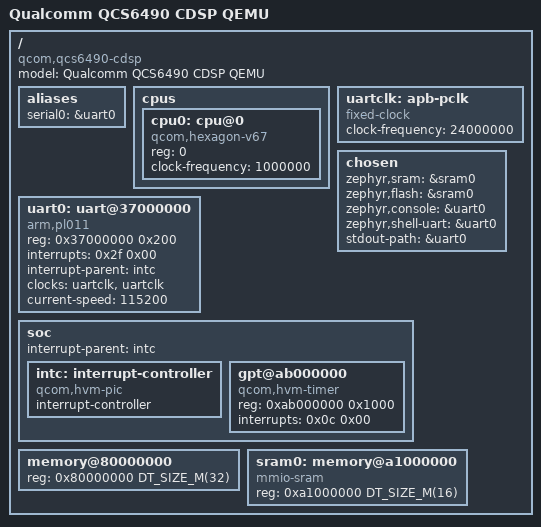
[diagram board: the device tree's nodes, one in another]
/*
 * Copyright (c) Qualcomm Technologies, Inc. and/or its subsidiaries.
 *
 * SPDX-License-Identifier: Apache-2.0
 */

/dts-v1/;

#include <mem.h>

/ {
	model = "Qualcomm QCS6490 CDSP QEMU";
	compatible = "qcom,qcs6490-cdsp";
	#address-cells = <1>;
	#size-cells = <1>;

	aliases {
		serial0 = &uart0;
	};

	cpus {
		#address-cells = <1>;
		#size-cells = <0>;

		cpu0: cpu@0 {
			device_type = "cpu";
			compatible = "qcom,hexagon-v67";
			reg = <0>;
			clock-frequency = <1000000>;
		};
	};

	uartclk: apb-pclk {
		compatible = "fixed-clock";
		clock-frequency = <24000000>;
		#clock-cells = <0>;
	};

	chosen {
		zephyr,sram = &sram0;
		zephyr,flash = &sram0;
		zephyr,console = &uart0;
		zephyr,shell-uart = &uart0;
		stdout-path = &uart0;
	};

	/* PL011 UART provided by the QCS6490 CDSP machine */
	uart0: uart@37000000 {
		compatible = "arm,pl011", "arm,primecell";
		reg = <0x37000000 0x200>;
		interrupts = <0x2f 0x00>;
		interrupt-names = "irq_0";
		interrupt-parent = <&intc>;
		clocks = <&uartclk &uartclk>;
		clock-names = "uartclk", "apb_pclk";
		status = "okay";
		current-speed = <115200>;
	};

	soc {
		#address-cells = <1>;
		#size-cells = <1>;
		ranges;
		interrupt-parent = <&intc>;

		intc: interrupt-controller {
			compatible = "qcom,hvm-pic";
			interrupt-controller;
			#interrupt-cells = <2>;
			#address-cells = <1>;
		};

		gpt@ab000000 {
			compatible = "qcom,hvm-timer";
			reg = <0xab000000 0x1000>;
			interrupts = <0x0c 0x00>;
		};
	};

	/* Main system memory */
	memory@80000000 {
		device_type = "memory";
		reg = <0x80000000 DT_SIZE_M(32)>;
	};

	/* SRAM for code and data */
	sram0: memory@a1000000 {
		device_type = "memory";
		compatible = "mmio-sram";
		reg = <0xa1000000 DT_SIZE_M(16)>;
	};
};
